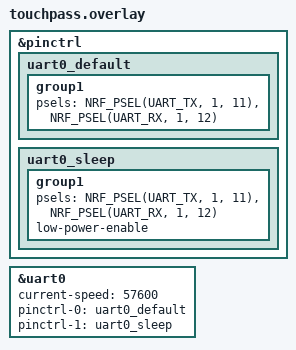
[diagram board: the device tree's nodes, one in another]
#include "touchpass.dtsi"

&pinctrl {
    uart0_default: uart0_default {
        group1 {
            psels = <NRF_PSEL(UART_TX, 1, 11)>,
                    <NRF_PSEL(UART_RX, 1, 12)>;
        };
    };

    uart0_sleep: uart0_sleep {
        group1 {
            psels = <NRF_PSEL(UART_TX, 1, 11)>,
                    <NRF_PSEL(UART_RX, 1, 12)>;
            low-power-enable;
        };
    };
};

&uart0 {
    status = "okay";
    current-speed = <57600>;
    pinctrl-0 = <&uart0_default>;
    pinctrl-1 = <&uart0_sleep>;
    pinctrl-names = "default", "sleep";
};
